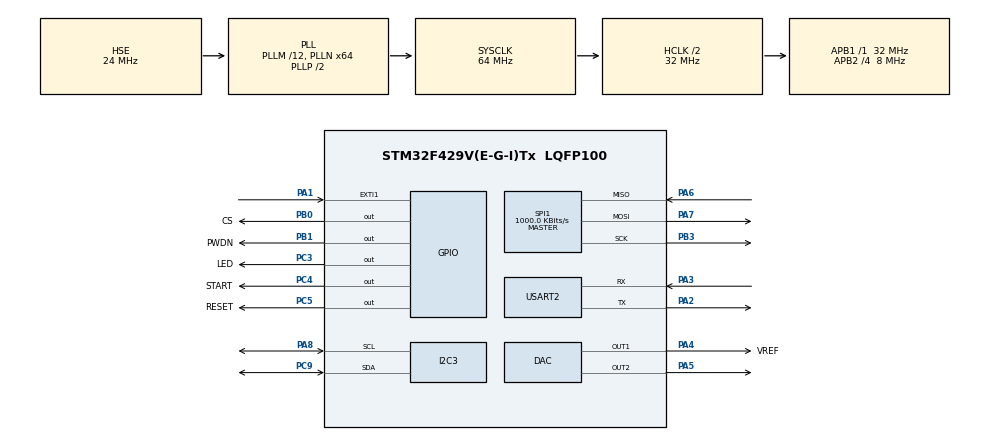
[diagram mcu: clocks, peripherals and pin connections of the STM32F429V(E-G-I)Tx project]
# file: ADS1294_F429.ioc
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I2C3.DutyCycle=I2C_DUTYCYCLE_16_9
I2C3.I2C_Mode=I2C_Fast
Mcu.Family=STM32F4
Mcu.Name=STM32F429V(E-G-I)Tx
Mcu.Package=LQFP100
NVIC.EXTI1_IRQn=true\:0\:0\:false\:false\:true\:true
NVIC.I2C3_ER_IRQn=true\:0\:0\:false\:false\:true\:true
NVIC.I2C3_EV_IRQn=true\:0\:0\:false\:false\:true\:true
NVIC.PriorityGroup=NVIC_PRIORITYGROUP_4
PA1.GPIO_PuPd=GPIO_PULLUP
PA1.Signal=GPXTI1
PA2.Mode=Asynchronous
PA2.Signal=USART2_TX
PA3.Mode=Asynchronous
PA3.Signal=USART2_RX
PA4.GPIO_Label=VREF
PA4.Signal=COMP_DAC1_group
PA5.Signal=COMP_DAC2_group
PA6.GPIO_PuPd=GPIO_PULLUP
PA6.GPIO_Speed=GPIO_SPEED_FREQ_MEDIUM
PA6.Mode=Full_Duplex_Master
PA6.Signal=SPI1_MISO
PA7.GPIO_Speed=GPIO_SPEED_FREQ_HIGH
PA7.Mode=Full_Duplex_Master
PA7.Signal=SPI1_MOSI
PA8.Mode=I2C
PA8.Signal=I2C3_SCL
PB0.GPIO_Label=CS
PB0.Signal=GPIO_Output
PB1.GPIO_Label=PWDN
PB1.Signal=GPIO_Output
PB3.GPIO_Speed=GPIO_SPEED_FREQ_MEDIUM
PB3.Mode=Full_Duplex_Master
PB3.Signal=SPI1_SCK
PC3.GPIO_Label=LED
PC3.Signal=GPIO_Output
PC4.GPIO_Label=START
PC4.Signal=GPIO_Output
PC5.GPIO_Label=RESET
PC5.Signal=GPIO_Output
PC9.Mode=I2C
PC9.Signal=I2C3_SDA
PH0/OSC_IN.Mode=HSE-External-Oscillator
PH0/OSC_IN.Signal=RCC_OSC_IN
PH1/OSC_OUT.Mode=HSE-External-Oscillator
PH1/OSC_OUT.Signal=RCC_OSC_OUT
ProjectManager.HeapSize=0x200
ProjectManager.StackSize=0x400
ProjectManager.TargetToolchain=EWARM
RCC.48MHZClocksFreq_Value=32000000
RCC.AHBCLKDivider=RCC_SYSCLK_DIV2
RCC.AHBFreq_Value=32000000
RCC.APB1Freq_Value=32000000
RCC.APB1TimFreq_Value=32000000
RCC.APB2CLKDivider=RCC_HCLK_DIV4
RCC.APB2Freq_Value=8000000
RCC.APB2TimFreq_Value=16000000
RCC.CortexFreq_Value=32000000
RCC.HCLKFreq_Value=32000000
RCC.HSE_VALUE=24000000
RCC.HSI_VALUE=16000000
RCC.LSE_VALUE=32768
RCC.PLLM=12
RCC.PLLN=64
RCC.PLLSourceVirtual=RCC_PLLSOURCE_HSE
RCC.SYSCLKFreq_VALUE=64000000
RCC.SYSCLKSource=RCC_SYSCLKSOURCE_PLLCLK
RCC.VCOOutputFreq_Value=128000000
SH.COMP_DAC1_group.0=DAC_OUT1,DAC_OUT1
SH.COMP_DAC2_group.0=DAC_OUT2,DAC_OUT2
SPI1.BaudRatePrescaler=SPI_BAUDRATEPRESCALER_8
SPI1.CLKPhase=SPI_PHASE_2EDGE
SPI1.CalculateBaudRate=1000.0 KBits/s
SPI1.Direction=SPI_DIRECTION_2LINES
SPI1.Mode=SPI_MODE_MASTER
SPI1.VirtualType=VM_MASTER
USART2.VirtualMode=VM_ASYNC
board=ADS1294_F429

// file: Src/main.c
/**
  ******************************************************************************
  * File Name          : main.c
  * Description        : Main program body
  ******************************************************************************
  ** This notice applies to any and all portions of this file
  * that are not between comment pairs USER CODE BEGIN and
  * USER CODE END. Other portions of this file, whether
  * inserted by the user or by software development tools
  * are owned by their respective copyright owners.
  *
  * COPYRIGHT(c) 2018 STMicroelectronics
  *
  * Redistribution and use in source and binary forms, with or without modification,
  * are permitted provided that the following conditions are met:
  *   1. Redistributions of source code must retain the above copyright notice,
  *      this list of conditions and the following disclaimer.
  *   2. Redistributions in binary form must reproduce the above copyright notice,
  *      this list of conditions and the following disclaimer in the documentation
  *      and/or other materials provided with the distribution.
  *   3. Neither the name of STMicroelectronics nor the names of its contributors
  *      may be used to endorse or promote products derived from this software
  *      without specific prior written permission.
  *
  * THIS SOFTWARE IS PROVIDED BY THE COPYRIGHT HOLDERS AND CONTRIBUTORS "AS IS"
  * AND ANY EXPRESS OR IMPLIED WARRANTIES, INCLUDING, BUT NOT LIMITED TO, THE
  * IMPLIED WARRANTIES OF MERCHANTABILITY AND FITNESS FOR A PARTICULAR PURPOSE ARE
  * DISCLAIMED. IN NO EVENT SHALL THE COPYRIGHT HOLDER OR CONTRIBUTORS BE LIABLE
  * FOR ANY DIRECT, INDIRECT, INCIDENTAL, SPECIAL, EXEMPLARY, OR CONSEQUENTIAL
  * DAMAGES (INCLUDING, BUT NOT LIMITED TO, PROCUREMENT OF SUBSTITUTE GOODS OR
  * SERVICES; LOSS OF USE, DATA, OR PROFITS; OR BUSINESS INTERRUPTION) HOWEVER
  * CAUSED AND ON ANY THEORY OF LIABILITY, WHETHER IN CONTRACT, STRICT LIABILITY,
  * OR TORT (INCLUDING NEGLIGENCE OR OTHERWISE) ARISING IN ANY WAY OUT OF THE USE
  * OF THIS SOFTWARE, EVEN IF ADVISED OF THE POSSIBILITY OF SUCH DAMAGE.
  *
  ******************************************************************************
  */
#include "main.h"
#include "stm32f4xx_hal.h"

/* USER CODE BEGIN Includes */
#include "ADS1294.h"
#include "Hamamatsu.h"
/* USER CODE END Includes */

DAC_HandleTypeDef hdac;

I2C_HandleTypeDef hi2c3;

SPI_HandleTypeDef hspi1;

UART_HandleTypeDef huart2;

/* USER CODE BEGIN PV */
/* Private variables ---------------------------------------------------------*/

/* USER CODE END PV */

void SystemClock_Config(void);
static void MX_GPIO_Init(void);
static void MX_DAC_Init(void);
static void MX_SPI1_Init(void);
static void MX_USART2_UART_Init(void);
static void MX_I2C3_Init(void);

/* USER CODE BEGIN PFP */
/* Private function prototypes -----------------------------------------------*/

/* USER CODE END PFP */

int main(void)
{

  /* MCU Configuration----------------------------------------------------------*/

  /* Reset of all peripherals, Initializes the Flash interface and the Systick. */
  HAL_Init();

  /* Configure the system clock */
  SystemClock_Config();

  /* Initialize all configured peripherals */
  MX_GPIO_Init();
  MX_DAC_Init();
  MX_SPI1_Init();
  MX_USART2_UART_Init();
  MX_I2C3_Init();

  /* USER CODE BEGIN 2 */

  /*HAL_NVIC_DisableIRQ(EXTI1_IRQn);
  Init_ADS1294(&hspi1,&hdac);
  HAL_NVIC_EnableIRQ(EXTI1_IRQn);
  HAL_DAC_Start(&hdac,DAC_CHANNEL_2);*/

  //Hamamatsu_INIT(&hi2c3);
  //Registers_STAT(&hi2c3);

  //HAL_Delay(500);
  //Hamamatsu_INIT(&hi2c3);
  //Fixed_teme_mode(&hi2c3);
  //Manual_setting_mode(&hi2c3);

  /* USER CODE END 2 */

  /* Infinite loop */
  while (1)
  {

  /* USER CODE BEGIN 3 */

/*
HAL_DAC_SetValue(&hdac,DAC_CHANNEL_2,DAC_ALIGN_12B_R,1035);
HAL_Delay(100);
HAL_DAC_SetValue(&hdac,DAC_CHANNEL_2,DAC_ALIGN_12B_R,517);
HAL_Delay(100);*/
  }
  /* USER CODE END 3 */

}

/** System Clock Configuration
*/
void SystemClock_Config(void)
{

  RCC_OscInitTypeDef RCC_OscInitStruct;
  RCC_ClkInitTypeDef RCC_ClkInitStruct;

    /**Configure the main internal regulator output voltage
    */
  __HAL_RCC_PWR_CLK_ENABLE();

  __HAL_PWR_VOLTAGESCALING_CONFIG(PWR_REGULATOR_VOLTAGE_SCALE3);

    /**Initializes the CPU, AHB and APB busses clocks
    */
  RCC_OscInitStruct.OscillatorType = RCC_OSCILLATORTYPE_HSE;
  RCC_OscInitStruct.HSEState = RCC_HSE_ON;
  RCC_OscInitStruct.PLL.PLLState = RCC_PLL_ON;
  RCC_OscInitStruct.PLL.PLLSource = RCC_PLLSOURCE_HSE;
  RCC_OscInitStruct.PLL.PLLM = 12;
  RCC_OscInitStruct.PLL.PLLN = 64;
  RCC_OscInitStruct.PLL.PLLP = RCC_PLLP_DIV2;
  RCC_OscInitStruct.PLL.PLLQ = 4;
  if (HAL_RCC_OscConfig(&RCC_OscInitStruct) != HAL_OK)
  {
    _Error_Handler(__FILE__, __LINE__);
  }

    /**Initializes the CPU, AHB and APB busses clocks
    */
  RCC_ClkInitStruct.ClockType = RCC_CLOCKTYPE_HCLK|RCC_CLOCKTYPE_SYSCLK
                              |RCC_CLOCKTYPE_PCLK1|RCC_CLOCKTYPE_PCLK2;
  RCC_ClkInitStruct.SYSCLKSource = RCC_SYSCLKSOURCE_PLLCLK;
  RCC_ClkInitStruct.AHBCLKDivider = RCC_SYSCLK_DIV2;
  RCC_ClkInitStruct.APB1CLKDivider = RCC_HCLK_DIV1;
  RCC_ClkInitStruct.APB2CLKDivider = RCC_HCLK_DIV4;

  if (HAL_RCC_ClockConfig(&RCC_ClkInitStruct, FLASH_LATENCY_1) != HAL_OK)
  {
    _Error_Handler(__FILE__, __LINE__);
  }

    /**Configure the Systick interrupt time
    */
  HAL_SYSTICK_Config(HAL_RCC_GetHCLKFreq()/1000);

    /**Configure the Systick
    */
  HAL_SYSTICK_CLKSourceConfig(SYSTICK_CLKSOURCE_HCLK);

  /* SysTick_IRQn interrupt configuration */
  HAL_NVIC_SetPriority(SysTick_IRQn, 0, 0);
}

/* DAC init function */
static void MX_DAC_Init(void)
{

  DAC_ChannelConfTypeDef sConfig;

    /**DAC Initialization
    */
  hdac.Instance = DAC;
  if (HAL_DAC_Init(&hdac) != HAL_OK)
  {
    _Error_Handler(__FILE__, __LINE__);
  }

    /**DAC channel OUT1 config
    */
  sConfig.DAC_Trigger = DAC_TRIGGER_NONE;
  sConfig.DAC_OutputBuffer = DAC_OUTPUTBUFFER_ENABLE;
  if (HAL_DAC_ConfigChannel(&hdac, &sConfig, DAC_CHANNEL_1) != HAL_OK)
  {
    _Error_Handler(__FILE__, __LINE__);
  }

    /**DAC channel OUT2 config
    */
  if (HAL_DAC_ConfigChannel(&hdac, &sConfig, DAC_CHANNEL_2) != HAL_OK)
  {
    _Error_Handler(__FILE__, __LINE__);
  }

}

/* I2C3 init function */
static void MX_I2C3_Init(void)
{

  hi2c3.Instance = I2C3;
  hi2c3.Init.ClockSpeed = 400000;
  hi2c3.Init.DutyCycle = I2C_DUTYCYCLE_16_9;
  hi2c3.Init.OwnAddress1 = 0;
  hi2c3.Init.AddressingMode = I2C_ADDRESSINGMODE_7BIT;
  hi2c3.Init.DualAddressMode = I2C_DUALADDRESS_DISABLE;
  hi2c3.Init.OwnAddress2 = 0;
  hi2c3.Init.GeneralCallMode = I2C_GENERALCALL_DISABLE;
  hi2c3.Init.NoStretchMode = I2C_NOSTRETCH_DISABLE;
  if (HAL_I2C_Init(&hi2c3) != HAL_OK)
  {
    _Error_Handler(__FILE__, __LINE__);
  }

}

/* SPI1 init function */
static void MX_SPI1_Init(void)
{

  /* SPI1 parameter configuration*/
  hspi1.Instance = SPI1;
  hspi1.Init.Mode = SPI_MODE_MASTER;
  hspi1.Init.Direction = SPI_DIRECTION_2LINES;
  hspi1.Init.DataSize = SPI_DATASIZE_8BIT;
  hspi1.Init.CLKPolarity = SPI_POLARITY_LOW;
  hspi1.Init.CLKPhase = SPI_PHASE_2EDGE;
  hspi1.Init.NSS = SPI_NSS_SOFT;
  hspi1.Init.BaudRatePrescaler = SPI_BAUDRATEPRESCALER_8;
  hspi1.Init.FirstBit = SPI_FIRSTBIT_MSB;
  hspi1.Init.TIMode = SPI_TIMODE_DISABLE;
  hspi1.Init.CRCCalculation = SPI_CRCCALCULATION_DISABLE;
  hspi1.Init.CRCPolynomial = 10;
  if (HAL_SPI_Init(&hspi1) != HAL_OK)
  {
    _Error_Handler(__FILE__, __LINE__);
  }

}

/* USART2 init function */
static void MX_USART2_UART_Init(void)
{

  huart2.Instance = USART2;
  huart2.Init.BaudRate = 115200;
  huart2.Init.WordLength = UART_WORDLENGTH_8B;
  huart2.Init.StopBits = UART_STOPBITS_1;
  huart2.Init.Parity = UART_PARITY_NONE;
  huart2.Init.Mode = UART_MODE_TX_RX;
  huart2.Init.HwFlowCtl = UART_HWCONTROL_NONE;
  huart2.Init.OverSampling = UART_OVERSAMPLING_16;
  if (HAL_UART_Init(&huart2) != HAL_OK)
  {
    _Error_Handler(__FILE__, __LINE__);
  }

}

/** Configure pins as
        * Analog
        * Input
        * Output
        * EVENT_OUT
        * EXTI
*/
static void MX_GPIO_Init(void)
{

  GPIO_InitTypeDef GPIO_InitStruct;

  /* GPIO Ports Clock Enable */
  __HAL_RCC_GPIOH_CLK_ENABLE();
  __HAL_RCC_GPIOC_CLK_ENABLE();
  __HAL_RCC_GPIOA_CLK_ENABLE();
  __HAL_RCC_GPIOB_CLK_ENABLE();

  /*Configure GPIO pin Output Level */
  HAL_GPIO_WritePin(GPIOC, LED_Pin|START_Pin|RESET_Pin, GPIO_PIN_RESET);

  /*Configure GPIO pin Output Level */
  HAL_GPIO_WritePin(GPIOB, CS_Pin|PWDN_Pin, GPIO_PIN_RESET);

  /*Configure GPIO pins : LED_Pin START_Pin RESET_Pin */
  GPIO_InitStruct.Pin = LED_Pin|START_Pin|RESET_Pin;
  GPIO_InitStruct.Mode = GPIO_MODE_OUTPUT_PP;
  GPIO_InitStruct.Pull = GPIO_NOPULL;
  GPIO_InitStruct.Speed = GPIO_SPEED_FREQ_LOW;
  HAL_GPIO_Init(GPIOC, &GPIO_InitStruct);

  /*Configure GPIO pin : PA1 */
  GPIO_InitStruct.Pin = GPIO_PIN_1;
  GPIO_InitStruct.Mode = GPIO_MODE_IT_RISING;
  GPIO_InitStruct.Pull = GPIO_PULLUP;
  HAL_GPIO_Init(GPIOA, &GPIO_InitStruct);

  /*Configure GPIO pins : CS_Pin PWDN_Pin */
  GPIO_InitStruct.Pin = CS_Pin|PWDN_Pin;
  GPIO_InitStruct.Mode = GPIO_MODE_OUTPUT_PP;
  GPIO_InitStruct.Pull = GPIO_NOPULL;
  GPIO_InitStruct.Speed = GPIO_SPEED_FREQ_LOW;
  HAL_GPIO_Init(GPIOB, &GPIO_InitStruct);

  /* EXTI interrupt init*/
  HAL_NVIC_SetPriority(EXTI1_IRQn, 0, 0);
  HAL_NVIC_EnableIRQ(EXTI1_IRQn);

}

/* USER CODE BEGIN 4 */

/*void EXTI1_IRQHandler(void)
{
if(EXTI->PR & (1 << 1) ){
        EXTI->PR = 1 << 1;
     }
     ReadData(&hspi1,&huart2);
}*/

/* USER CODE END 4 */

void _Error_Handler(char * file, int line)
{
  while(1)
  {
  }
}

/************************ (C) COPYRIGHT STMicroelectronics *****END OF FILE****/
